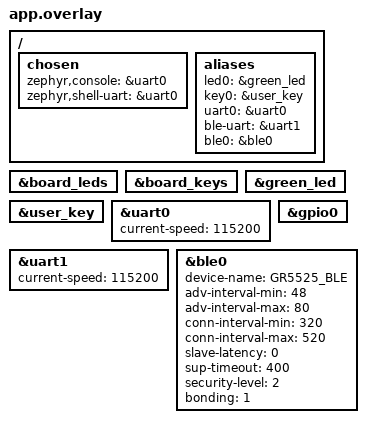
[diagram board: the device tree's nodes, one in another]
&board_leds { status = "okay"; };
&board_keys { status = "okay"; };

/ {
    chosen {
        zephyr,console = &uart0;
        zephyr,shell-uart = &uart0;
    };
    aliases {
        led0 = &green_led;
        key0 = &user_key;
        uart0 = &uart0;
        ble-uart = &uart1;
        ble0 = &ble0;
    };
};

&green_led {
    status = "okay";
};

&user_key {
    status = "okay";
};

&uart0 {
    status = "okay";
    current-speed = <115200>;
};

&uart1 {
    status = "okay";
    current-speed = <115200>;
};

&gpio0 {
    status = "okay";
};

&ble0 {
    status = "okay";
    device-name = "GR5525_BLE";
    adv-interval-min = <48>;
    adv-interval-max = <80>;
    conn-interval-min = <320>;
    conn-interval-max = <520>;
    slave-latency = <0>;
    sup-timeout = <400>;
    security-level = <2>;
    bonding = <1>;
};
